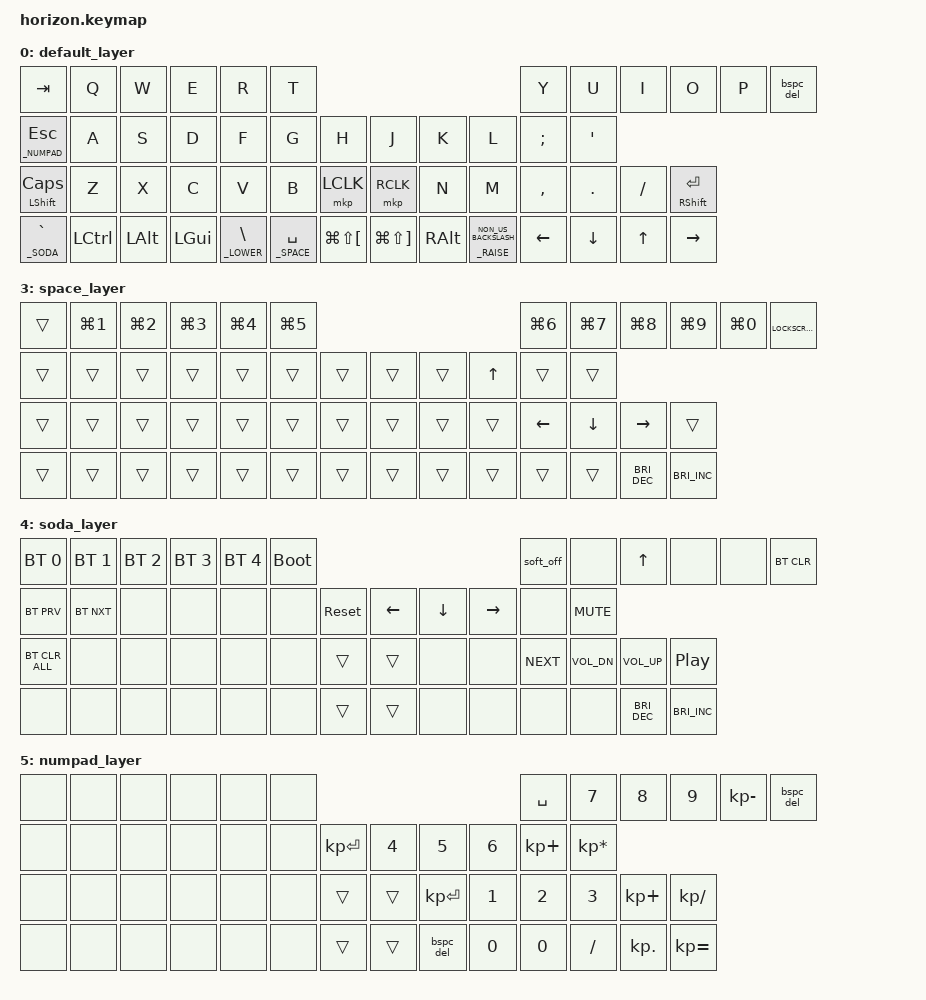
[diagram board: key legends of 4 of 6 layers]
/*
 * Copyright (c) 2026 Arda Kilicdagi
 *
 * SPDX-License-Identifier: MIT
 */

#include <behaviors.dtsi>
#include <dt-bindings/zmk/keys.h>
#include <dt-bindings/zmk/bt.h>
#include <dt-bindings/zmk/pointing.h>


// For QMK:
// KC_NONUS_BSLASH (\|) is equivalent to ["é] key in Turkish keyboards.
// KC_GRV (~ `) is equivalent to [<>|] key in Turkish keyboards.
// KC_SCLN is Turkish s [şŞ] key
// KC_QUOT is Turkish i [iİ] key
// KC_COMM is Turkish o [öÖ] key
// KC_DOT is Turkish c [çÇ] key

// For ZMK:
// NON_US_BACKSLASH (\|) is equivalent to ["é] key in Turkish keyboards.
// GRAVE (~ `) is equivalent to [<>|] key in Turkish keyboards.
// SEMI (;) is Turkish s [şŞ] key
// SQT (') is Turkish i [iİ] key
// COMMA (,) is Turkish o [öÖ] key
// DOT (.) is Turkish c [çÇ] key
// FSLH (/) is Turkish dot [.:] key
// BSLH (\) is Turkish comma (,;) key

// Custom shortcuts specific to Turkish layout
#define _CURLY_OPEN RA(N7)
#define _CURLY_CLOSE RA(N0)
#define _AT_SIGN RA(Q)
#define _SQUARE_OPEN RA(N8)
#define _SQUARE_CLOSE RA(N9)
#define _DOLLAR_SIGN RA(N4)
#define _BACKSLASH RA(MINUS)
#define _VERTICAL_PIPE RA(EQUAL)
#define _BACKTICK RA(BACKSLASH)
#define _TILDE RA(RIGHT_BRACKET)
#define _NUMBER_SIGN RA(N3) //hashtag sign
#define _LOCKSCREEN LC(LS(C_PWR)) // Screen Lock shortcut for OSX

// Layers
#define _QWERTY 0
#define _LOWER 1
#define _RAISE 2
#define _SPACE 3
#define _SODA 4
#define _NUMPAD 5

/ {
    behaviors {
        bspc_del: backspace_delete {
            compatible = "zmk,behavior-mod-morph";
            #binding-cells = <0>;
            bindings = <&kp BSPC>, <&kp DEL>;
            mods = <(MOD_LSFT|MOD_RSFT)>;
        };
    };

    keymap {
        compatible = "zmk,keymap";

        default_layer {
        /* Qwerty
        * ,--------------------------------------------------------------------------------------------------.
        * |  Tab |   Q  |   W  |   E  |   R  |   T  |              |   Y  |   U  |   I  |   O  |   P  | Bksp |
        * |------+------+------+------+------+------|              |------+------+------+------+------+------|
        * |NPdEsc|   A  |   S  |   D  |   F  |   G  |              |   H  |   J  |   K  |   L  |   Ş  |   İ  |
        * |------+------+------+------+------+------+------+-------+------+------+------+------+------+------|
        * |SftCps|   Z  |   X  |   C  |   V  |   B  |LftClk|RgtClk |   N  |   M  |   Ö  |   Ç  |   .  |SftEtr|
        * |------+------+------+------+------+------+------+-------+------+------+------+------+------+------|
        * |Sda|<>| Ctrl | LAlt |  OS  |Lowr|,|Space*|PrvTab|NxtTab | RALT |Rise|"| Left | Down |  Up  |Right |
        * `--------------------------------------------------------------------------------------------------'
        */
            bindings = <
    &kp TAB  &kp Q  &kp W  &kp E  &kp R  &kp T  &kp Y  &kp U  &kp I  &kp O  &kp P  &bspc_del
    &lt _NUMPAD ESC  &kp A  &kp S  &kp D  &kp F  &kp G  &kp H  &kp J  &kp K  &kp L  &kp SEMI  &kp SQT
    &mt LSHFT CLCK  &kp Z  &kp X  &kp C  &kp V  &kp B  &mkp LCLK  &mkp RCLK  &kp N  &kp M  &kp COMMA  &kp DOT  &kp FSLH  &mt RSHFT RET
    &lt _SODA GRAVE  &kp LCTRL  &kp LALT  &kp LGUI  &lt _LOWER BSLH  &lt _SPACE SPACE  &kp LG(LS(LEFT_BRACKET))  &kp LG(LS(RIGHT_BRACKET))  &kp RALT &lt _RAISE NON_US_BACKSLASH  &kp LEFT  &kp DOWN  &kp UP  &kp RIGHT
            >;
        };

        lower_layer {
        /* Lower
        * ,--------------------------------------------------------------------------------------------------.
        * |   >  |   !  |   '  |   ^  |   +  |   %  |              |   &  |   /  |   (  |   )  |   =  | Bksp |
        * |------+------+------+------+------+------|              |------+------+------+------+------+------|
        * |  F1  |  F2  |  F3  |  F4  |  F5  |  F6  |              |   `_  |   ?  |   _  |  Ğ   |  Ü   |  -   |
        * |------+------+------+------+------+------+------+-------+------+------+------+------+------+------|
        * |  F7  |  F8  |  F9  |  F10 |  F11 |  F12 |      |       |      |  "$" |  "{" |  "}" |  <   |  ">" |
        * |------+------+------+------+------+------+------+-------+------+------+------+------+------+------|
        * |      |      |      |      |      |      |      |       |      |      |  "[" |  "]" |  '   |   "  |
        * `--------------------------------------------------------------------------------------------------'
        */
            bindings = <
    &kp TILDE  &kp EXCL  &kp AT  &kp HASH  &kp DLLR  &kp PRCNT  &kp CARET  &kp AMPS  &kp ASTERISK  &kp LPAR  &kp RPAR  &bspc_del
    &kp F1  &kp F2  &kp F3  &kp F4  &kp F5  &kp F6  &kp _BACKTICK  &kp UNDERSCORE  &kp PLUS  &kp LEFT_BRACKET  &kp RIGHT_BRACKET  &kp EQUAL  &trans
    &kp F7  &kp F8  &kp F9  &kp F10  &kp F11  &kp F12  &trans  &trans  &trans  &kp _DOLLAR_SIGN  &kp _CURLY_OPEN  &kp _CURLY_CLOSE  &kp GRAVE  &kp LS(GRAVE)
    &trans  &trans  &trans  &trans  &trans  &trans  &trans  &trans  &trans  &trans  &kp _SQUARE_OPEN  &kp _SQUARE_CLOSE  &kp AT  &kp NON_US_BACKSLASH
            >;
        };

        raise_layer {
        /* Raise
        * ,--------------------------------------------------------------------------------------------------.
        * |  <>| |   1  |   2  |   3  |   4  |   5  |              |   6  |   7  |   8  |   9  |   0  | Bksp |
        * |------+------+------+------+------+------|              |------+------+------+------+------+------|
        * |  F1  |  F2  |  F3  |  F4  |  F5  |  F6  |              |   `_  |   *  |   -  | "\"  | "|"  |  ,  |
        * |------+------+------+------+------+------+------+-------+------+------+------+------+------+------|
        * |  F7  |  F8  |  F9  |  F10 |  F11 |  F12 |      |       |      |   #  |   "  | "~"  | "`"  |  <>| |
        * |------+------+------+------+------+------+------+-------+------+------+------+------+------+------|
        * |      |      |      |      |      |      |      |       |      |      | Next | Vol- | Vol+ | Play |
        * `--------------------------------------------------------------------------------------------------'
        */
            bindings = <
    &kp GRAVE  &kp N1  &kp N2  &kp N3  &kp N4  &kp N5  &kp N6  &kp N7  &kp N8  &kp N9  &kp N0  &bspc_del
    &kp F1  &kp F2  &kp F3  &kp F4  &kp F5  &kp F6  &kp _BACKTICK  &kp MINUS  &kp EQUAL  &kp _BACKSLASH  &kp _VERTICAL_PIPE  &kp BACKSLASH  &trans
    &kp F7  &kp F8  &kp F9  &kp F10  &kp F11  &kp F12  &trans  &trans  &trans  &kp _NUMBER_SIGN  &kp NON_US_BSLH  &kp _TILDE  &kp _BACKTICK  &kp GRAVE
    &trans  &trans  &trans  &trans  &trans  &trans  &trans  &trans  &trans  &trans  &kp C_NEXT  &kp C_VOL_DN  &kp C_VOL_UP  &kp C_PLAY_PAUSE
            >;
        };

        space_layer {
        /* Space Layer (Space Bar Layer Tap)
        * ,--------------------------------------------------------------------------------------------------.
        * |      |CMD+1 |CMD+2 |CMD+3 |CMD+4 |CMD+5 |              |CMD+6 |CMD+7 |CMD+8 |CMD+9 |CMD+0 |LCKOSX|
        * |------+------+------+------+------+------|              |------+------+------+------+------+------|
        * |      |      |      |      |      |      |              |      |      |      |  Up  |      |      |
        * |------+------+------+------+------+------+------+-------+------+------+------+------+------+------|
        * |      |      |      |      |      |      |      |       |      |      | Left | Down |Right |      |
        * |------+------+------+------+------+------+------+-------+------+------+------+------+------+------|
        * |      |      |      |      |      |      |      |       |      |      |      |      |Brght▼|Brght▲|
        * `--------------------------------------------------------------------------------------------------'
        */
            bindings = <
    &trans  &kp LG(N1)  &kp LG(N2)  &kp LG(N3)  &kp LG(N4)  &kp LG(N5)  &kp LG(N6)  &kp LG(N7)  &kp LG(N8)  &kp LG(N9)  &kp LG(N0)  &kp _LOCKSCREEN
    &trans  &trans  &trans  &trans  &trans  &trans  &trans  &trans  &trans  &kp UP  &trans  &trans
    &trans  &trans  &trans  &trans  &trans  &trans  &trans  &trans  &trans  &trans  &kp LEFT  &kp DOWN  &kp RIGHT  &trans
    &trans  &trans  &trans  &trans  &trans  &trans  &trans  &trans  &trans  &trans  &trans  &trans  &kp C_BRI_DEC  &kp C_BRI_INC
            >;
        };

        soda_layer {
        /* Soda Layer (Adjust and other stuff)
        * ,--------------------------------------------------------------------------------------------------.
        * | BT 0 | BT 1 | BT 2 | BT 3 | BT 4 |BtLdr |              |SftOff|      |  Up  |      |      |BT CLR|
        * |------+------+------+------+------+------|              |------+------+------+------+------+------|
        * |BT Prv|BT Nxt|      |      |      |      |              | Reset| Left | Down |Right |      | Mute |
        * |------+------+------+------+------+------+------+-------+------+------+------+------+------+------|
        * |BTClrA|      |      |      |      |      |      |       |      |      | Next | Vol- | Vol+ | Play |
        * |------+------+------+------+------+------+------+-------+------+------+------+------+------+------|
        * |      |      |      |      |      |      |      |       |      |      |      |      |Brght▼|Brght▲|
        * `--------------------------------------------------------------------------------------------------'
        */
            bindings = <
    &bt BT_SEL 0  &bt BT_SEL 1  &bt BT_SEL 2  &bt BT_SEL 3  &bt BT_SEL 4  &bootloader  &soft_off  &none  &kp UP  &none  &none  &bt BT_CLR
    &bt BT_PRV  &bt BT_NXT  &none  &none  &none  &none  &sys_reset  &kp LEFT  &kp DOWN  &kp RIGHT  &none  &kp C_MUTE
    &bt BT_CLR_ALL  &none  &none  &none  &none  &none  &trans  &trans  &none  &none  &kp C_NEXT  &kp C_VOL_DN  &kp C_VOL_UP  &kp C_PLAY_PAUSE
    &none  &none  &none  &none  &none  &none  &trans  &trans  &none  &none  &none  &none  &kp C_BRI_DEC  &kp C_BRI_INC
            >;
        };

        numpad_layer {
        /* Numpad Layer
        * KC_PDOT is comma on the Turkish layout ¯\_(ツ)_/¯
        * ,--------------------------------------------------------------------------------------------------.
        * |      |      |      |      |      |      |              | Space|   7  |   8  |   9  |   -  | Bksp |
        * |------+------+------+------+------+------|              |------+------+------+------+------+------|
        * |      |      |      |      |      |      |              | Enter|   4  |   5  |   6  |   +  |   *  |
        * |------+------+------+------+------+------+------+-------+------+------+------+------+------+------|
        * |      |      |      |      |      |      |      |       | Enter|   1  |   2  |   3  |   +  |   /  |
        * |------+------+------+------+------+------+------+-------+------+------+------+------+------+------|
        * |      |      |      |      |      |      |      |       | Bksp |   0  |   0  |   .  |   ,  |   =  |
        * `--------------------------------------------------------------------------------------------------'
        */
            bindings = <
    &none  &none  &none  &none  &none  &none  &kp SPACE  &kp N7  &kp N8  &kp N9  &kp KP_MINUS  &bspc_del
    &none  &none  &none  &none  &none  &none  &kp KP_ENTER  &kp N4  &kp N5  &kp N6  &kp KP_PLUS  &kp KP_ASTERISK
    &none  &none  &none  &none  &none  &none  &trans  &trans  &kp KP_ENTER  &kp N1  &kp N2  &kp N3  &kp KP_PLUS  &kp KP_SLASH
    &none  &none  &none  &none  &none  &none  &trans  &trans  &bspc_del  &kp N0  &kp N0  &kp SLASH  &kp KP_DOT  &kp KP_EQUAL
            >;
        };
    };
};
